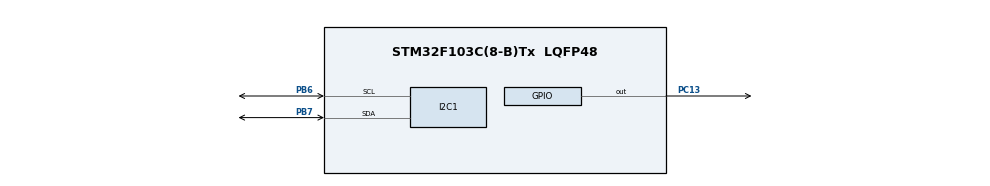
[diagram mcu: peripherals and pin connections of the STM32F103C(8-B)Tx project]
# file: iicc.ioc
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Mcu.Family=STM32F1
Mcu.Name=STM32F103C(8-B)Tx
Mcu.Package=LQFP48
NVIC.PriorityGroup=NVIC_PRIORITYGROUP_4
PA13.Mode=Serial_Wire
PA13.Signal=SYS_JTMS-SWDIO
PA14.Mode=Serial_Wire
PA14.Signal=SYS_JTCK-SWCLK
PB6.Mode=I2C
PB6.Signal=I2C1_SCL
PB7.Mode=I2C
PB7.Signal=I2C1_SDA
PC13-TAMPER-RTC.Signal=GPIO_Output
PD0-OSC_IN.Mode=HSE-External-Oscillator
PD0-OSC_IN.Signal=RCC_OSC_IN
PD1-OSC_OUT.Mode=HSE-External-Oscillator
PD1-OSC_OUT.Signal=RCC_OSC_OUT
ProjectManager.HeapSize=0x200
ProjectManager.StackSize=0x400
ProjectManager.TargetToolchain=MDK-ARM V5
RCC.APB1Freq_Value=8000000
RCC.APB2Freq_Value=8000000
board=custom

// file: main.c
/* USER CODE BEGIN Header */
/**
  ******************************************************************************
  * @file           : main.c
  * @brief          : Main program body
  ******************************************************************************
  * @attention
  *
  * Copyright (c) 2024 STMicroelectronics.
  * All rights reserved.
  *
  * This software is licensed under terms that can be found in the LICENSE file
  * in the root directory of this software component.
  * If no LICENSE file comes with this software, it is provided AS-IS.
  *
  ******************************************************************************
  */
/* USER CODE END Header */
#include "main.h"
/* USER CODE BEGIN Includes */
#include "string.h"
#include "stdio.h"
/* USER CODE END Includes */

/* USER CODE BEGIN PM */
#define addr_pcf8574 0x27<<1
/* USER CODE END PM */

I2C_HandleTypeDef hi2c1;

void SystemClock_Config(void);
static void MX_GPIO_Init(void);
static void MX_I2C1_Init(void);
/* USER CODE BEGIN PFP */
void LCD_I2C_Write_CMD(uint8_t data)
{
uint8_t buf[4] ={(data&0xF0)|0x04 , (data&0xF0)|0x00 ,(data<<4)|0x04 ,(data<<4)|0x00};
HAL_I2C_Master_Transmit (&hi2c1,addr_pcf8574,buf,4,HAL_MAX_DELAY);
}
void LCD_I2C_Write_Data(uint8_t data)
{
uint8_t buf[4] ={(data&0xF0)|0x05 , (data&0xF0)|0x01 ,(data<<4)|0x05 ,(data<<4)|0x01};
HAL_I2C_Master_Transmit (&hi2c1,addr_pcf8574,buf,4,HAL_MAX_DELAY);
}
void LCD_I2C_Init()
{LCD_I2C_Write_CMD(0x33);
	LCD_I2C_Write_CMD(0x32);
	LCD_I2C_Write_CMD(0x28);
	LCD_I2C_Write_CMD(0x0C);
	LCD_I2C_Write_CMD(0x06);
	LCD_I2C_Write_CMD(0x01);
	HAL_Delay(2);
}
void LCD_I2C_Clear()
{	LCD_I2C_Write_CMD(0x01);
	HAL_Delay(2);}
void LCD_I2C_Location (uint8_t x,uint8_t y)
{if(x==0)
	LCD_I2C_Write_CMD(0x80+y);
	else if(x==1)
		LCD_I2C_Write_CMD(0xC0+y);
}
void LCD_I2C_Write_String(char* string)
{for( uint8_t i=0;i<strlen(string);i++)
	{LCD_I2C_Write_Data(string[i]);
	}
}
void LCD_I2C_Write_Num(int num)
{char buffer[8];
	sprintf(buffer,"%d",num);
	LCD_I2C_Write_String(buffer);
}
/* USER CODE END PFP */

int main(void)
{

  /* MCU Configuration--------------------------------------------------------*/

  /* Reset of all peripherals, Initializes the Flash interface and the Systick. */
  HAL_Init();

  /* Configure the system clock */
  SystemClock_Config();

  /* Initialize all configured peripherals */
  MX_GPIO_Init();
  MX_I2C1_Init();
  /* USER CODE BEGIN 2 */
LCD_I2C_Init();

  /* USER CODE END 2 */

  /* Infinite loop */
  while (1)
  {
LCD_I2C_Location(0,0);
		LCD_I2C_Write_String("Wipe card!");
		LCD_I2C_Location(1,0);
		LCD_I2C_Write_Num(2024);
		HAL_Delay(1500);
		LCD_I2C_Clear();
		HAL_Delay(1000);
  }
}

void SystemClock_Config(void)
{
  RCC_OscInitTypeDef RCC_OscInitStruct = {0};
  RCC_ClkInitTypeDef RCC_ClkInitStruct = {0};

  /** Initializes the RCC Oscillators according to the specified parameters
  * in the RCC_OscInitTypeDef structure.
  */
  RCC_OscInitStruct.OscillatorType = RCC_OSCILLATORTYPE_HSI;
  RCC_OscInitStruct.HSIState = RCC_HSI_ON;
  RCC_OscInitStruct.HSICalibrationValue = RCC_HSICALIBRATION_DEFAULT;
  RCC_OscInitStruct.PLL.PLLState = RCC_PLL_NONE;
  if (HAL_RCC_OscConfig(&RCC_OscInitStruct) != HAL_OK)
  {
    Error_Handler();
  }

  /** Initializes the CPU, AHB and APB buses clocks
  */
  RCC_ClkInitStruct.ClockType = RCC_CLOCKTYPE_HCLK|RCC_CLOCKTYPE_SYSCLK
                              |RCC_CLOCKTYPE_PCLK1|RCC_CLOCKTYPE_PCLK2;
  RCC_ClkInitStruct.SYSCLKSource = RCC_SYSCLKSOURCE_HSI;
  RCC_ClkInitStruct.AHBCLKDivider = RCC_SYSCLK_DIV1;
  RCC_ClkInitStruct.APB1CLKDivider = RCC_HCLK_DIV1;
  RCC_ClkInitStruct.APB2CLKDivider = RCC_HCLK_DIV1;

  if (HAL_RCC_ClockConfig(&RCC_ClkInitStruct, FLASH_LATENCY_0) != HAL_OK)
  {
    Error_Handler();
  }
}

static void MX_I2C1_Init(void)
{

  hi2c1.Instance = I2C1;
  hi2c1.Init.ClockSpeed = 100000;
  hi2c1.Init.DutyCycle = I2C_DUTYCYCLE_2;
  hi2c1.Init.OwnAddress1 = 0;
  hi2c1.Init.AddressingMode = I2C_ADDRESSINGMODE_7BIT;
  hi2c1.Init.DualAddressMode = I2C_DUALADDRESS_DISABLE;
  hi2c1.Init.OwnAddress2 = 0;
  hi2c1.Init.GeneralCallMode = I2C_GENERALCALL_DISABLE;
  hi2c1.Init.NoStretchMode = I2C_NOSTRETCH_DISABLE;
  if (HAL_I2C_Init(&hi2c1) != HAL_OK)
  {
    Error_Handler();
  }

}

static void MX_GPIO_Init(void)
{
  GPIO_InitTypeDef GPIO_InitStruct = {0};

  /* GPIO Ports Clock Enable */
  __HAL_RCC_GPIOC_CLK_ENABLE();
  __HAL_RCC_GPIOD_CLK_ENABLE();
  __HAL_RCC_GPIOA_CLK_ENABLE();
  __HAL_RCC_GPIOB_CLK_ENABLE();

  /*Configure GPIO pin Output Level */
  HAL_GPIO_WritePin(GPIOC, GPIO_PIN_13, GPIO_PIN_RESET);

  /*Configure GPIO pin : PC13 */
  GPIO_InitStruct.Pin = GPIO_PIN_13;
  GPIO_InitStruct.Mode = GPIO_MODE_OUTPUT_PP;
  GPIO_InitStruct.Pull = GPIO_NOPULL;
  GPIO_InitStruct.Speed = GPIO_SPEED_FREQ_LOW;
  HAL_GPIO_Init(GPIOC, &GPIO_InitStruct);

}

void Error_Handler(void)
{
  __disable_irq();
  while (1)
  {
  }
}
